# tviic2d6mddr register map
Vendor: Cypress Semiconductor; Series: tviic2d6mddr; File version: 1.0
CPU: CM7 r0p1, little endian, MPU, FPU, VTOR, 3 interrupt priority bits
Registers are 32-bit, read-write, reset 0x0 unless marked. A register's access mark holds for its fields unless they carry their own. Offsets are from the block's base; [hi:lo] are bit positions; lines under a group give offsets from that group; {n}, {i} and the like mark numbered series; 'fields as' and 'values as' point back to an identical list; <NAME> marks a mode.

## PASS0 — Programmable Analog Subsystem for S40E
Base 0x40900000
{0x0+0x1000*i} SAR[{i}] (i=0..1) group — SAR ADC with Sequencer for S40E
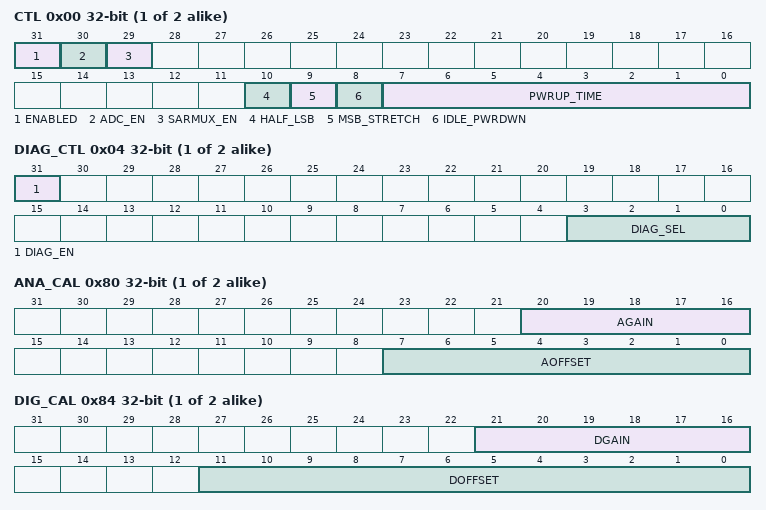
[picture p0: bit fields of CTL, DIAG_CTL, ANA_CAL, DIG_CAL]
  0x00 CTL — Analog control register.
    [31] ENABLED — - 0: SAR IP disabled (put analog in power down and stop clocks), also clears all pending triggers. - 1: SAR IP enabled.
    [30] ADC_EN — Enable the SAR ADC and SAR sequencer (only valid if ENABLED=1) - 0: SARADC and SARSEQ are disabled (put SARADC analog in power down and stop clocks), also clears all pending triggers. - 1: SAR ADC and SARSEQ are enabled. To enable ADC0 to borrow SARMUX1-3 the corresponding ADC_EN must be set to 0.
    [29] SARMUX_EN — Enable the SARMUX (only valid if ENABLED=1) - 0: SARMUX disabled (put analog in power down) - 1: SARMUX enabled.
    [10] HALF_LSB — When set take an extra cycle to convert the half LSB and add it to 12-bit result for Missing Code Recovery This bit should always be set to '1' - 0: disable half LSB conversion (not recommended) - 1: enable half LSB conversion
    [9] MSB_STRETCH — When set use 2 cycles for the Most Significant Bit (MSB) - 0: Use 1 clock cycle for MSB - 1: Use 2 clock cycles for MSB
    [8] IDLE_PWRDWN — When idle automatically power down the analog. After an automatic power down a new trigger will power up the analog, however it will take PWRUP_TIME cycles before the first acquisition can be started. Note that re-arbitration happens at that time, i.e. the trigger that caused the power up may not get handled first.
    [7:0] PWRUP_TIME — Number cycles to wait to power up after IDLE_PWRDWN. Check the STATUS.PWRUP_BUSY flag to see if the delay is still in progress. The power up delay is 1 us.
  0x04 DIAG_CTL — Diagnostic Reference control register.
    [31] DIAG_EN — Diagnostic Reference enable (only valid if ENABLED=1) - 0: Diagnostic Reference disabled (powered down resistor ladder and current mirrors, DiagOut = Vssa). - 1: Diagnostic Reference enabled, output signal select according to DIAG_SEL (note also EPASS_MMIO.PASS_CTL.REFBUF_EN must be set).
    [3:0] DIAG_SEL — Select Diagnostic Reference function
      0=VREFL (DiagOut = VrefL); {v}=VREFH_{v}DIV8 (DiagOut = VrefH * {v}/8) (v=1..7); 8=VREFH (DiagOut = VrefH); 9=VREFX (DiagOut = VrefX = VrefH * 199/200); 10=VBG (DiagOut = Vbg from SRSS); 11=VIN1 (DiagOut = Vin1); 12=VIN2 (DiagOut = Vin2); 13=VIN3 (DiagOut = Vin3); 14=I_SOURCE (DiagOut = Isource (10uA)); 15=I_SINK (DiagOut = Isink (10uA))
  0x10 PRECOND_CTL — Preconditioning control register.
    [3:0] PRECOND_TIME — Number ADC clock cycles that Preconditioning is done before the sample window starts. If OVERLAP_EN=0 there will be 1 additional break before make cycle between preconditioning and sampling. Note that the minimum value is 1 (0 gives the same result as 1).
  0x80 ANA_CAL — Current analog calibration values
    [20:16] AGAIN — Analog gain correction
    [7:0] AOFFSET — Analog offset correction
  0x84 DIG_CAL — Current digital calibration values
    [21:16] DGAIN — Digital gain correction. Signed value to correct +/- 30 codes for the maximum input voltage. Corrected = (D - DOFFSET) + ( (D - DOFFSET) * DGAIN + 0x800) / 0x1000
    [11:0] DOFFSET — Digital offset correction Subtract DOFFSET from ADC output.
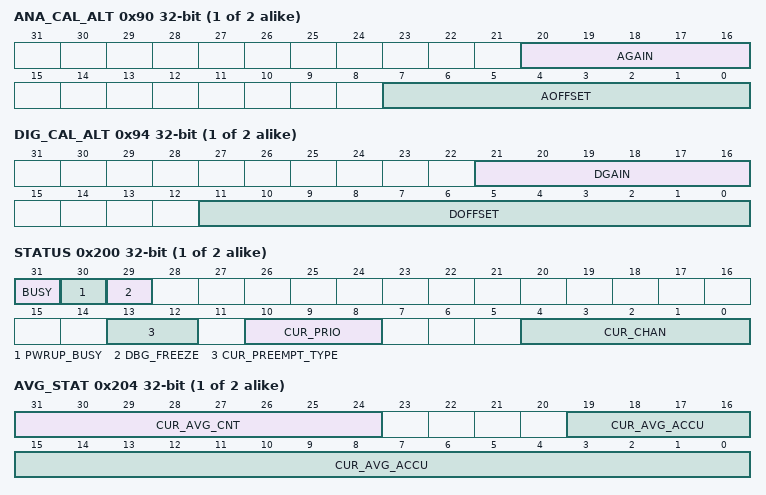
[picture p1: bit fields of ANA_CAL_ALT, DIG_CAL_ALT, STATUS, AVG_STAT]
  0x90 ANA_CAL_ALT — Alternate analog calibration values
    [20:16] AGAIN — See corresponding ANA_CAL field
    [7:0] AOFFSET — See corresponding ANA_CAL field
  0x94 DIG_CAL_ALT — Alternate digital calibration values
    [21:16] DGAIN — See corresponding DIG_CAL field
    [11:0] DOFFSET — See corresponding DIG_CAL field
  0x98 CAL_UPD_CMD — Calibration update command
    [0] UPDATE — Calibration update command: coherently copy values from alternate calibration regs to current calibration regs. Software sets this bit when the alternate calibration values have been set with the new values. Hardware will do the calibration update as soon as the ADC is idle or a 'continuous' triggered group completes. This ensures that all acquisitions within a group scan (even if preempted) are done with the same calibration values. This bit is cleared at the same time the calibration update is done. By clearing this bit software can cancel a requested update. Note: if the ADC is always busy with acquisitions for non continuously triggered groups/channels then the calibration update will remain pending forever. In such a case the software can either do a non coherent update by writing directly to the current calibration registers, or software can force the ADC to idle by disabling some or all channels. Software can check/poll this bit to see if the calibration update has taken effect.
  0x100 TR_PEND ro — Trigger pending status
    [31:0] TR_PEND — Trigger Pending. Hardware will set this bit if a hardware trigger is received.
  0x180 WORK_VALID ro — Channel working data register 'valid' bits
    [31:0] WORK_VALID — If set the corresponding WORK register is valid, i.e. was already acquired during the current group scan. If this bit is low then either the channel is not enabled, not yet acquired or it is used as a pulse detect channel.
  0x184 WORK_RANGE ro — Range detected
  0x188 WORK_RANGE_HI ro — Range detect above Hi flag
    [31:0] ABOVE_HI — Out of range was detected and the value was above the Hi threshold
  0x18C WORK_PULSE ro — Pulse detected
  0x1A0 RESULT_VALID ro — Channel result data register 'valid' bits
    [31:0] RESULT_VALID — If set the corresponding RESULT register is valid, i.e. was acquired during the preceding group scan. If this bit is low, after a group scan completed, then either the channel is not enabled or is used as a pulse detect channel.
  0x1A4 RESULT_RANGE_HI ro — Channel Range above Hi flags
    fields as SAR[0].WORK_RANGE_HI
  0x200 STATUS ro — Current status of internal SAR registers (mostly for debug)
    [31] BUSY — If high then the SAR is busy with a conversion.
    [30] PWRUP_BUSY — If high then the SAR is waiting for PWRUP_TIME due to IDLE_PWRDWN
    [29] DBG_FREEZE — If high then the SAR is prevented from starting a new acquisition, see DBG_FREEZE_EN.
    [13:12] CUR_PREEMPT_TYPE — Preempting type of current group/channel, only valid if BUSY.
    [10:8] CUR_PRIO — priority of current group/channel, only valid if BUSY.
    [4:0] CUR_CHAN — current channel being acquired, only valid if BUSY.
  0x204 AVG_STAT ro — Current averaging status (for debug)
    [31:24] CUR_AVG_CNT — the current value of the averaging counter. Note that the value shown is updated after the sample window and therefore runs ahead of the accumulator update.
    [19:0] CUR_AVG_ACCU — the current value of the averaging accumulator
  {0x800+0x40*j} CH[{j}] (j=0..31) group — Channel structure
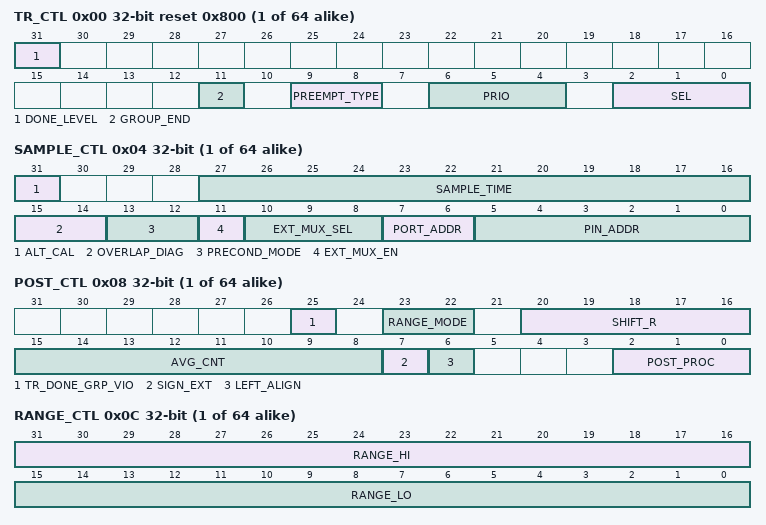
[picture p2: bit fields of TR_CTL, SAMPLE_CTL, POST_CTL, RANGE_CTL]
    0x00 TR_CTL reset 0x800 — Trigger control.
      [31] DONE_LEVEL — select level or pulse for 'tr_ch_done' trigger output Also see POST_CTL.TR_DONE_GRP_VIO
        0=PULSE (tr_ch_done generates a 2 cycle pulse (clk_sys), no need to read the result to clear (also no ch_overflow detection)); 1=LEVEL (tr_ch_done is a level output until the result register is read (typical for DW usage, this also enables ch_overflow detection when DW is too slow))
      [11] GROUP_END — 0: continue group with next channel 1: last channel of a group. Note that for the channel with the highest index (SAR_CH_NR) this always needs to be set
      [9:8] PREEMPT_TYPE — Preemption type allow for this group
        0=ABORT_CANCEL (Abort ongoing acquisition, do not return Clear pending trigger for aborted group and set Cancelled interrupt. Also 'Abort' whenever this group (do not pend the trigger) is not immediately scheduled for acquisition after a new trigger arrives. For this preemption type only, only a positive edge on the trigger can trigger the channel, i.e. CONTINUOUS or level high operation is not supported (to avoid continuous Cancelled interrupts). In case CTL.IDLE_PWRDWN is used and the analog is powered down, the group cannot be immediately scheduled for acquisition and therefore a trigger for a group with this preemption type will power up the analog, but the group will ABORT and set the Cancelled interrupt); 1=ABORT_RESTART (Abort ongoing acquisition, up on return Restart group from first channel.); 2=ABORT_RESUME (Abort ongoing acquisition, up on return Resume group from aborted channel If averaging, discard averaging results so far and restart averaging.); 3=FINISH_RESUME (Complete ongoing acquisition (including averaging), up on return Resume group from next channel)
      [6:4] PRIO — Channel priority: '0': highest priority. '1' ... '6' '7': lowest priority. Channels with the same priority constitute a priority level. Priority decoding determines the highest priority pending channel. This channel is determined as follows. First, the highest priority level with pending channels is identified. Second, within this priority level, round robin arbitration is applied. Round robin arbitration (within a priority level) gives the highest priority to the lower channel indices (within the priority level).
      [2:0] SEL — Trigger select
        0=OFF (Use for channels in group, except the first channel); 1=TCPWM (Trigger from corresponding TCPWM channel); 2=GENERIC0 (Generic trigger input 0); {v}=GENERIC{v-2} (N/A) (v=3..6); 7=CONTINUOUS (Always triggered (also called idle), can only be used for at most 1 channel)
    0x04 SAMPLE_CTL reset not defined — Sample control.
      [31] ALT_CAL — Use alternate calibration values instead of the current calibration values. This allows the firmware to allocate one or more channels to quietly re-calibrate the ADC in the background of regular processing. 0 = use regular calibration values (ANA/DIG_CAL) 1 = use alternate calibration values (ANA/DIG_CAL_ALT) Note: typically calibration measurements select VrefL (PIN_ADDR=62) or VrefH (PIN_ADDR=63)
      [27:16] SAMPLE_TIME — Sample time (aperture) in ADC clock cycles. Minimum is 1 (0 gives the same result as 1), minimum time needed for proper settling is at least 300ns, i.e. 6 clock cycles at the max frequency of 20MHz.
      [15:14] OVERLAP_DIAG — Select Overlap mode or SARMUX Diagnostics, in both cases the Diagnostic reference is used. With Overlap the Diagnostic reference typically sources or sinks a small current which is connected at the same time as the analog signal being sampled. For SARMUX Diagnostics the Diagnostic reference should provide a reference voltage which is selected at the SARMUX input instead of the normal analog signal being sampled.
        0=OFF (No overlap or SARMUX Diagnostics); 1=HALF (Sample the selected analog input for 2 SAMPLE_TIME periods. During the first period use overlap sampling, i.e. connect both the analog input and Diagnostic reference. During second period only connect the analog input.); 2=FULL (Like normal sample the selected analog input for a single SAMPLE_TIME period but use overlap sampling, i.e. connect both the analog input and Diagnostic reference.); 3=MUX_DIAG (Select Diagnostic reference instead of analog signal at the input of the SARMUX. This enables a functional safety check of the SARMUX analog connections.)
      [13:12] PRECOND_MODE — Select preconditioning mode. Preconditioning (dis)charges the SAR sample capacitor to the selected reference voltage for PRECOND_TIME (global) cycles, a break before make cycle will be inserted before sampling starts (SAMPLE_TIME).
        0=OFF (No preconditioning); 1=VREFL (Discharge to VREFL); 2=VREFH (Charge to VREFH); 3=DIAG (Connect the Diagnostic reference output during preconditioning. The Diagnostic reference should be configured to output a reference voltage. Note: this selection is mutual exclusive with using the Diagnostic reference to supply an ibias current for OVERLAP.)
      [11] EXT_MUX_EN — External analog mux enable. This enable can be used as enable (chip select) for the external analog mux (this enable is not used as enable for the GPIO output driver). This enable also prevents unnecessary toggle activity on the select signals of the external analog mux. When this enable is low EXT_MUX_SEL value will be ignored and the previous value will be maintained. Note that an external analog mux can only be used in combination with a pin input, i.e. PIN_ADDR<32 or Vmotor. If an internal signal is selected this enable should be 0.
      [10:8] EXT_MUX_SEL — External analog mux select. This bit setting is related to EXT_MUX[x]_y on pin assignment. 0x0: Select EXT_MUX[x]_0 pin 0x1: Select EXT_MUX[x]_1 pin
      [7:6] PORT_ADDR — Select the physical port. This field is only valid for ADC0. ADC0 can control and connect to the SARMUX of the neighboring ADC1-3. This requires the corresponding ADC to be off while the SARMUX is left on. When ADC0 controls another SARMUX it uses the PIN_ADDR, EXT_MUX_EN/SEL of this channel to control the other SARMUX.
        0=SARMUX0 (ADC uses it's own SARMUX); 1=SARMUX1 (ADC0 uses SARMUX1 (only valid for ADC0, undefined result if used for ADC1-3)); 2=SARMUX2 (ADC0 uses SARMUX2 (only valid for ADC0, undefined result if used for ADC1-3)); 3=SARMUX3 (ADC0 uses SARMUX3 (only valid for ADC0, undefined result if used for ADC1-3))
      [5:0] PIN_ADDR
    0x08 POST_CTL reset not defined — Post processing control
      [25] TR_DONE_GRP_VIO — Select tr_sar_ch_done mode for last channel of a group, ignored for all other channels Also see TR_CTL.DONE_LEVEL
        0=DONE (Default: tr_sar_ch_done is set when the group is done); 1=GRP_RANGE_VIO (tr_sar_ch_done is only set if any of the channels in the group has a Range Violation. This mode is ignored if this is not the last channel in the group. Note that if none of the channels in the group have Range detection enabled then the trigger will never get set.)
      [23:22] RANGE_MODE — Range detect mode
        0=BELOW_LO (Below Low threshold (result < Lo)); 1=INSIDE_RANGE (Inside range (Lo <= result < Hi)); 2=ABOVE_HI (Above high threshold (Hi <= result)); 3=OUTSIDE_RANGE (Outside range (result < Lo || Hi <= result))
      [20:16] SHIFT_R — Either Shift Right (no pulse detection) or Pulse negative reload value (if pulse detection is enabled) Shift right SHIFT_R[3:0] = [0..12]: the result (typically after averaging) is shifted right as specified here. Software has to make sure that the result fits in less than 16 bits. Any value >12 will be treated as 12, bit [4] is always ignored. This can also be used to fit the 12-bit result in 8 bits. Pulse detect negative reload value PULSE_NEG_RL[4:0]
      [15:8] AVG_CNT — Either averaging count (minus 1) or Pulse positive reload value Averaging Count for channels that have averaging enabled. A channel will be sampled (AVG_CNT+1) = [1..256] times. The signal will be acquired back to back (1st order accumulate and dump filter), the average result is calculated and stored and then the next enabled channel is sampled. If more than 16 sample are taken (AVG_CNT>=16) then AVG_SHIFT must be set so that the result after shifting fits in 16 bits Pulse detect positive reload value PULSE_POS_RL[7:0]
      [7] SIGN_EXT — Output data is sign extended
        0=UNSIGNED (Default: result data is unsigned (zero extended if needed)); 1=SIGNED (Result data is signed (sign extended if needed))
      [6] LEFT_ALIGN — Left or right align data in result[15:0]. 0: the data is right aligned in result[11:0], with sign extension to 16 bits if enabled 1: the data is left aligned in result[15:4] with the lower nibble 0. Caveat if the result was more than 12 bits (e.g. after averaging) then the bits above 12 will be discarded.
      [2:0] POST_PROC — Post processing
        0=NONE (No postprocessing); 1=AVG (Averaging); 2=AVG_RANGE (Averaging followed by Range detect); 3=RANGE (Range detect); 4=RANGE_PULSE (Range detect followed by pulse detect); 5=RSVD0 (N/A); 6=RSVD1 (N/A); 7=RSVD2 (N/A)
    0x0C RANGE_CTL reset not defined — Range thresholds
      [31:16] RANGE_HI — Range detect high threshold (Hi)
      [15:0] RANGE_LO — Range detect low threshold (Lo)
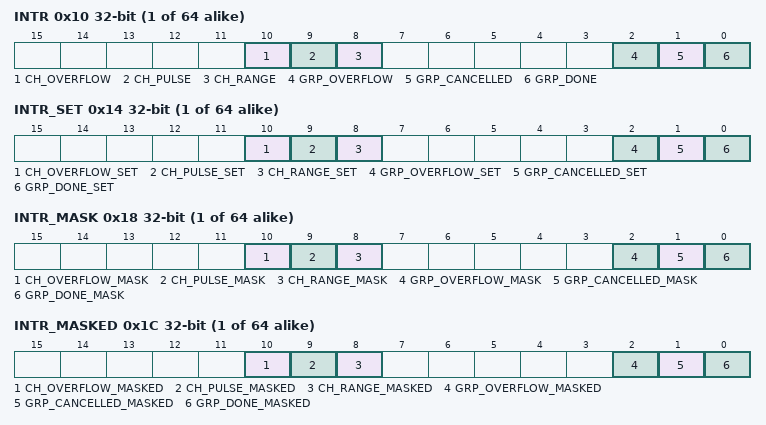
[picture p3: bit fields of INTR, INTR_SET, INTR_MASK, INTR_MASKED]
    0x10 INTR — Interrupt request register.
      [10] CH_OVERFLOW — Channel overflow Interrupt: hardware sets this interrupt for each channel if a new Pulse or Range interrupt is detected while the interrupt is still pending or when DW did not acknowledge data pickup. Write with '1' to clear bit.
      [9] CH_PULSE — Pulse detect Interrupt: hardware sets this interrupt for each channel if the positive pulse counter reaches zero. This interrupt is mutual exclusive with Range detect interrupt. Write with '1' to clear bit.
      [8] CH_RANGE — Range detect Interrupt: hardware sets this interrupt for each channel if the conversion result (after averaging) of that channel met the condition specified by the SAR_RANGE registers. This interrupt is mutual exclusive with Pulse detect interrupt. Write with '1' to clear bit.
      [2] GRP_OVERFLOW — Overflow Interrupt: hardware sets this interrupt for the last channel of a group if the group scan is done and the Done interrupt is already (still) pending. Write with '1' to clear bit.
      [1] GRP_CANCELLED — Cancelled Interrupt: hardware sets this interrupt for the last channel of a group if the group scan was preempted and CANCELLED. Note that it is possible that also the GRP_DONE interrupt is set. If that is the case one or more new triggers were detected while the group was already busy, i.e. triggers are too fast. Write with '1' to clear bit.
      [0] GRP_DONE — Done Interrupt: hardware sets this interrupt for the last channel of a group if the group scan is done. Write with '1' to clear bit.
    0x14 INTR_SET — Interrupt set request register
      [10] CH_OVERFLOW_SET — Write with '1' to set corresponding bit in interrupt request register.
      [9] CH_PULSE_SET — Write with '1' to set corresponding bit in interrupt request register.
      [8] CH_RANGE_SET — Write with '1' to set corresponding bit in interrupt request register.
      [2] GRP_OVERFLOW_SET — Write with '1' to set corresponding bit in interrupt request register.
      [1] GRP_CANCELLED_SET — Write with '1' to set corresponding bit in interrupt request register.
      [0] GRP_DONE_SET — Write with '1' to set corresponding bit in interrupt request register.
    0x18 INTR_MASK — Interrupt mask register.
      [10] CH_OVERFLOW_MASK — Mask bit for corresponding bit in interrupt request register.
      [9] CH_PULSE_MASK — Mask bit for corresponding bit in interrupt request register.
      [8] CH_RANGE_MASK — Mask bit for corresponding bit in interrupt request register.
      [2] GRP_OVERFLOW_MASK — Mask bit for corresponding bit in interrupt request register.
      [1] GRP_CANCELLED_MASK — Mask bit for corresponding bit in interrupt request register.
      [0] GRP_DONE_MASK — Mask bit for corresponding bit in interrupt request register.
    0x1C INTR_MASKED ro — Interrupt masked request register
      [10] CH_OVERFLOW_MASKED — Logical and of corresponding request and mask bits.
      [9] CH_PULSE_MASKED — Logical and of corresponding request and mask bits.
      [8] CH_RANGE_MASKED — Logical and of corresponding request and mask bits.
      [2] GRP_OVERFLOW_MASKED — Logical and of corresponding request and mask bits.
      [1] GRP_CANCELLED_MASKED — Logical and of corresponding request and mask bits.
      [0] GRP_DONE_MASKED — Logical and of corresponding request and mask bits.
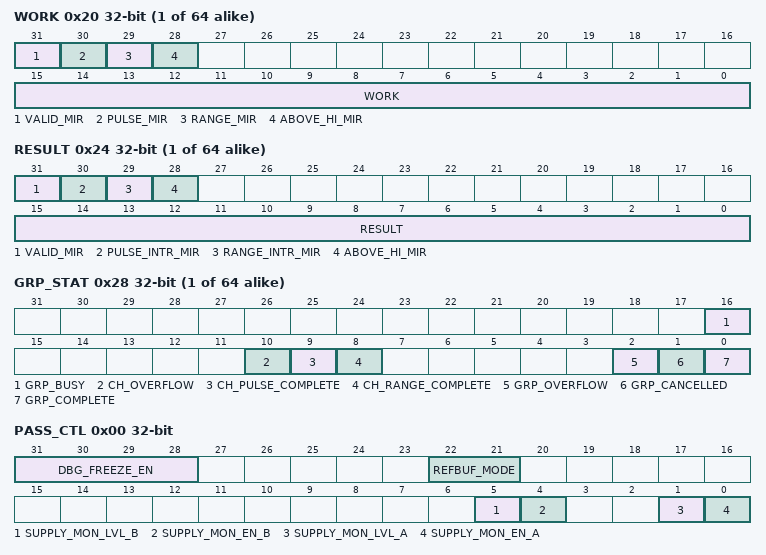
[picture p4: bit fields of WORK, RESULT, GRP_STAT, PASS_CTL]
    0x20 WORK ro (reset mask 0xF0000000) — Working data register
      [31] VALID_MIR — mirror bit of corresponding bit in WORK_VALID register
      [30] PULSE_MIR — mirror bit of corresponding bit in WORK_PULSE register
      [29] RANGE_MIR — mirror bit of corresponding bit in WORK_RANGE register
      [28] ABOVE_HI_MIR — mirror bit of the corresponding ABOVE_HI bit
      [15:0] WORK — SAR conversion working data of the channel. The data is written here right after sampling this channel.
    0x24 RESULT ro (reset mask 0xF0000000) — Result data register
      [31] VALID_MIR — mirror bit of the corresponding bit in RESULT_VALID register
      [30] PULSE_INTR_MIR — mirror bit of INTR.CH_PULSE bit
      [29] RANGE_INTR_MIR — mirror bit of INTR.CH_RANGE bit
      [28] ABOVE_HI_MIR — mirror bit of the corresponding ABOVE_HI bit
      [15:0] RESULT — SAR conversion result of the channel. The data is copied here from the WORK field after all enabled channels in this scan have been sampled.
    0x28 GRP_STAT ro — Group status register
      [16] GRP_BUSY — Group acquisition busy. This is a copy of the TR_PENDING bit of the first channel of the group.
      [10] CH_OVERFLOW — Channel Overflow. This is a copy of the INTR.CH_OVERFLOW bit.
      [9] CH_PULSE_COMPLETE — Channel Pulse complete. This is a copy of the INTR.CH_PULSE bit.
      [8] CH_RANGE_COMPLETE — Channel Range complete. This is a copy of the INTR.CH_RANGE bit.
      [2] GRP_OVERFLOW — Group Overflow. This is a copy of the INTR.GRP_OVERFLOW bit.
      [1] GRP_CANCELLED — Group Cancelled. This is a copy of the INTR.GRP_CANCELLED bit.
      [0] GRP_COMPLETE — Group acquisition complete. This is a copy of the INTR.GRP_DONE bit.
    0x38 ENABLE
      [0] CHAN_EN — Channel enable. - 0: the corresponding channel is disabled. Corresponding trigger will be reset immediately. - 1: the corresponding channel is enabled. Note: To disable a group either stop the trigger first or begin with disabling the lowest channel first. To enable a group either start with enabling the last channel first and the first channel last, or start the trigger after all channels are enabled. If these rules are not followed the result is undefined.
    0x3C TR_CMD — Software triggers
      [0] START — Software start trigger. When written with '1', a start trigger is generated which sets the corresponding TR_PEND bit (only if the channel is enabled). A read always returns a 0.
0xF0000 EPASS_MMIO group — PASS top-level MMIO (Generic Triggers)
  0x00 PASS_CTL — PASS control register
    [31:28] DBG_FREEZE_EN — Debug pause enable, 1 per ADC. When set a high tr_debug_freeze trigger will prevent the scheduler from starting acquisitions on a new channel. Note that averaging for an already started channel will be completed.
    [22:21] REFBUF_MODE — Reference mode. The reference needs to be present when using TEMP sensor or diagnostic reference (in addition to SAR.DIAG_CTL.DIAG_EN). Note that setting this mode is not required for the ADC operation itself.
      0=OFF (No reference); 1=ON (Reference = buffered Vbg from SRSS); 2=RSVD (undefined); 3=BYPASS (Reference = unbuffered Vbg from SRSS)
    [5] SUPPLY_MON_LVL_B — Supply monitor level select for AMUXBUS_B
      0=VRL (amuxbus_b_mon = VRL); 1=VRH (amuxbus_b_mon = VRH)
    [4] SUPPLY_MON_EN_B — Supply monitor enable for AMUXBUS_B (amuxbus_b_mon)
    [1] SUPPLY_MON_LVL_A — Supply monitor level select for AMUXBUS_A
      0=VRL (amuxbus_a_mon = VRL); 1=VRH (amuxbus_a_mon = VRH)
    [0] SUPPLY_MON_EN_A — Supply monitor enable for AMUXBUS_A (amuxbus_a_mon)
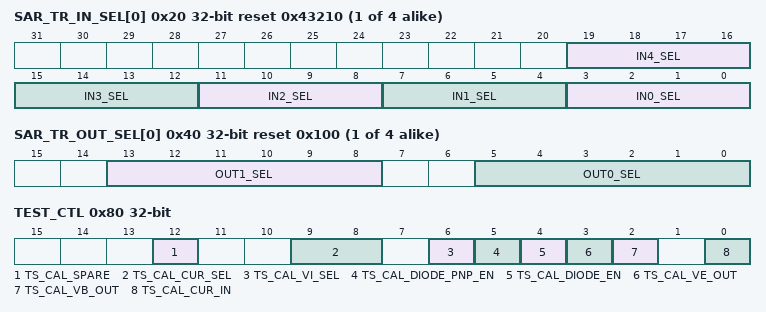
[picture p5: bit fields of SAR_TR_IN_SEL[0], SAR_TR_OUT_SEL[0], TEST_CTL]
  {0x20+4j} SAR_TR_IN_SEL[{j}] (j=0..3) reset 0x43210 — per SAR generic input trigger select
    [4n+3:4n] IN{n}_SEL (n=0..4) — Select generic trigger for SAR generic trigger input {n}
  {0x40+4j} SAR_TR_OUT_SEL[{j}] (j=0..3) reset 0x100 — per SAR generic output trigger select
    [13:8] OUT1_SEL — Select SAR output trigger for generic trigger output 1
    [5:0] OUT0_SEL — Select SAR output trigger for generic trigger output 0 0-31: selects a tr_sar_ch_done trigger 32-63: selects a tr_sar_ch_rangvio trigger
  0x80 TEST_CTL — Test control bits
    [12] TS_CAL_SPARE — Spare
    [9:8] TS_CAL_CUR_SEL — Select the current going into the BJT, for Temperature Sensor Calibration
      0=I_1U (Select 1 uA); 1=I_2U (Select 2 uA); 2=I_5U (Select 5 uA); 3=I_10U (Select 10 uA)
    [6] TS_CAL_VI_SEL — Select current or voltage output on 'v_temp' pin, for Temperature Sensor Calibration
      0=CURRENT (Current is selected); 1=VOLTAGE (Voltage is selected)
    [5] TS_CAL_DIODE_PNP_EN — Enable signal for PNP transistor. This transistor will be used only during calibration for accurate estimation of chip temp. 0 = Turn PNP off 1 = Configure PNP as a diode (short base and collector)
    [4] TS_CAL_DIODE_EN — Diode Enable, disconnect or connect the base and collector terminal of the BJT
    [3] TS_CAL_VE_OUT — Voltage Emitter switch control, for Temperature Sensor Calibration
    [2] TS_CAL_VB_OUT — Voltage Base switch control, for Temperature Sensor Calibration
    [0] TS_CAL_CUR_IN — External current input switch control, for Temperature Sensor Calibration
